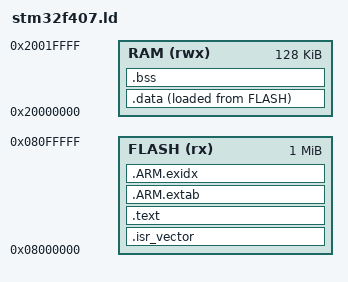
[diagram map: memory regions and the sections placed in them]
/* STM32F407VG — minimal bare-metal linker script.
 * Flash 1 MB @ 0x08000000, SRAM 128 KB @ 0x20000000.
 * Deliberately no CCM: the recorder ring buffer must live in ordinary SRAM so
 * that a real-hardware port has nothing special to reproduce. */

MEMORY
{
  FLASH (rx)  : ORIGIN = 0x08000000, LENGTH = 1024K
  RAM   (rwx) : ORIGIN = 0x20000000, LENGTH = 128K
}

_estack = ORIGIN(RAM) + LENGTH(RAM);

ENTRY(Reset_Handler)

SECTIONS
{
  .isr_vector :
  {
    KEEP(*(.isr_vector))
  } > FLASH

  .text :
  {
    . = ALIGN(4);
    *(.text)
    *(.text*)
    *(.rodata)
    *(.rodata*)
    . = ALIGN(4);
  } > FLASH

  /* ARM unwind tables — discarded, but the sections must be named or the
   * linker warns about orphans. */
  .ARM.extab : { *(.ARM.extab* .gnu.linkonce.armextab.*) } > FLASH
  .ARM.exidx : { *(.ARM.exidx* .gnu.linkonce.armexidx.*) } > FLASH

  _sidata = LOADADDR(.data);

  .data :
  {
    . = ALIGN(4);
    _sdata = .;
    *(.data)
    *(.data*)
    . = ALIGN(4);
    _edata = .;
  } > RAM AT > FLASH

  .bss :
  {
    . = ALIGN(4);
    _sbss = .;
    __bss_start__ = _sbss;
    *(.bss)
    *(.bss*)
    *(COMMON)
    . = ALIGN(4);
    _ebss = .;
    __bss_end__ = _ebss;
  } > RAM

  /DISCARD/ : { *(.note.GNU-stack) }
}
